VERSION ""

NS_ :

BS_:

BU_:

BO_ 1292 Aero_Static_Pressure_Array_1_3: 4 Vector__XXX
 SG_ P_Scanner_Temp : 23|16@0- (0.1,0) [-327.68|327.67] "C" Vector__XXX
 SG_ Aero_Static_REF : 7|16@0- (0.1,0) [-327.68|327.67] "mbar" Vector__XXX

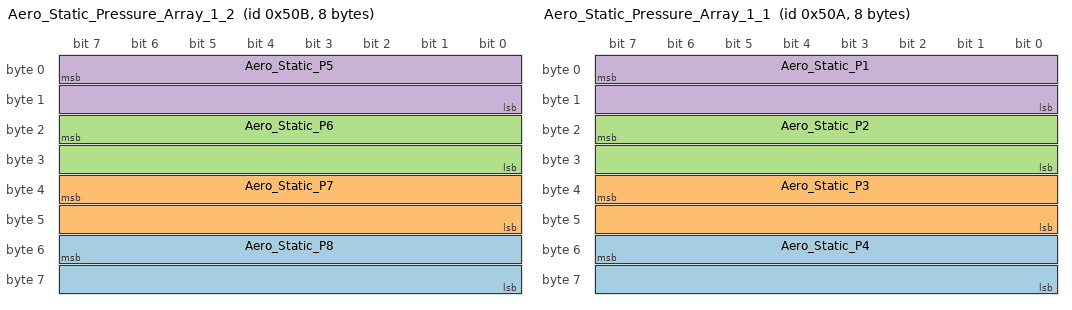
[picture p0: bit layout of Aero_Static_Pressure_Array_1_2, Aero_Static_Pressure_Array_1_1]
BO_ 1291 Aero_Static_Pressure_Array_1_2: 8 Vector__XXX
 SG_ Aero_Static_P8 : 55|16@0- (0.01,0) [-327.68|327.67] "mbar" Vector__XXX
 SG_ Aero_Static_P7 : 39|16@0- (0.01,0) [-327.68|327.67] "mbar" Vector__XXX
 SG_ Aero_Static_P6 : 23|16@0- (0.01,0) [-327.68|327.67] "mbar" Vector__XXX
 SG_ Aero_Static_P5 : 7|16@0- (0.01,0) [-327.68|327.67] "mbar" Vector__XXX

BO_ 1290 Aero_Static_Pressure_Array_1_1: 8 Vector__XXX
 SG_ Aero_Static_P4 : 55|16@0- (0.01,0) [-327.68|327.67] "mbar" Vector__XXX
 SG_ Aero_Static_P3 : 39|16@0- (0.01,0) [-327.68|327.67] "mbar" Vector__XXX
 SG_ Aero_Static_P2 : 23|16@0- (0.01,0) [-327.68|327.67] "mbar" Vector__XXX
 SG_ Aero_Static_P1 : 7|16@0- (0.01,0) [-327.68|327.67] "mbar" Vector__XXX

BA_DEF_ BO_  "GenMsgCycleTime" INT 0 65535;
BA_DEF_DEF_  "GenMsgCycleTime" 0;
BA_ "GenMsgCycleTime" BO_ 1292 4;
BA_ "GenMsgCycleTime" BO_ 1291 4;
BA_ "GenMsgCycleTime" BO_ 1290 4;
